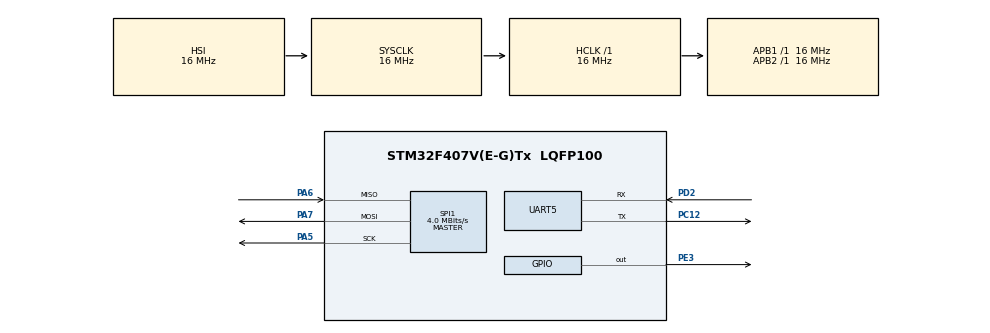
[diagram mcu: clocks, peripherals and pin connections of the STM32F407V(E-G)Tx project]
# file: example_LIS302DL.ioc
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Mcu.Family=STM32F4
Mcu.Name=STM32F407V(E-G)Tx
Mcu.Package=LQFP100
NVIC.PriorityGroup=NVIC_PRIORITYGROUP_4
PA5.Mode=Full_Duplex_Master
PA5.Signal=SPI1_SCK
PA6.Mode=Full_Duplex_Master
PA6.Signal=SPI1_MISO
PA7.Mode=Full_Duplex_Master
PA7.Signal=SPI1_MOSI
PC12.Mode=Asynchronous
PC12.Signal=UART5_TX
PD2.Mode=Asynchronous
PD2.Signal=UART5_RX
PE3.PinState=GPIO_PIN_SET
PE3.Signal=GPIO_Output
ProjectManager.HeapSize=0x200
ProjectManager.StackSize=0x400
ProjectManager.TargetToolchain=MDK-ARM V5.32
RCC.AHBFreq_Value=16000000
RCC.APB1Freq_Value=16000000
RCC.APB2Freq_Value=16000000
RCC.CortexFreq_Value=16000000
RCC.HSE_VALUE=25000000
RCC.HSI_VALUE=16000000
RCC.LSE_VALUE=32768
RCC.SYSCLKFreq_VALUE=16000000
RCC.VCOOutputFreq_Value=192000000
SPI1.BaudRatePrescaler=SPI_BAUDRATEPRESCALER_4
SPI1.CLKPhase=SPI_PHASE_2EDGE
SPI1.CLKPolarity=SPI_POLARITY_HIGH
SPI1.CalculateBaudRate=4.0 MBits/s
SPI1.Direction=SPI_DIRECTION_2LINES
SPI1.Mode=SPI_MODE_MASTER
SPI1.VirtualType=VM_MASTER
UART5.VirtualMode=Asynchronous
board=custom

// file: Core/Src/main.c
/* USER CODE BEGIN Header */
/**
  ******************************************************************************
  * @file           : main.c
  * @brief          : Main program body
  ******************************************************************************
  * @attention
  *
  * Copyright (c) 2026 STMicroelectronics.
  * All rights reserved.
  *
  * This software is licensed under terms that can be found in the LICENSE file
  * in the root directory of this software component.
  * If no LICENSE file comes with this software, it is provided AS-IS.
  *
  ******************************************************************************
  */
/* USER CODE END Header */
#include "main.h"
#include "spi.h"
#include "usart.h"
#include "gpio.h"

void SystemClock_Config(void);
/* USER CODE BEGIN PFP */
uint8_t MEMS_READ_REG(uint8_t reg_addr)
{
  uint8_t read_buf = reg_addr | 0x80;
  uint8_t recv_buf = 0;

  HAL_GPIO_WritePin(GPIOE, GPIO_PIN_3, GPIO_PIN_RESET);
  HAL_SPI_Transmit(&hspi1, &read_buf, 1, HAL_MAX_DELAY);
  HAL_SPI_Receive(&hspi1, &recv_buf, 1, HAL_MAX_DELAY);
  HAL_GPIO_WritePin(GPIOE, GPIO_PIN_3, GPIO_PIN_SET);

  return recv_buf;
}
/* USER CODE END PFP */

int main(void)
{

  /* MCU Configuration--------------------------------------------------------*/

  /* Reset of all peripherals, Initializes the Flash interface and the Systick. */
  HAL_Init();

  /* Configure the system clock */
  SystemClock_Config();

  /* Initialize all configured peripherals */
  MX_GPIO_Init();
  MX_SPI1_Init();
  MX_UART5_Init();
  /* USER CODE BEGIN 2 */
  uint8_t REG_WHO_AM_I = 0x0F;

  uint8_t READ_WHO_AM_I = REG_WHO_AM_I | 0x80;

  uint8_t recv_buf = 0;

  /* USER CODE END 2 */

  /* Infinite loop */
  while (1)
  {

    /* USER CODE BEGIN 3 */
    // HAL_GPIO_WritePin(GPIOE, GPIO_PIN_3, GPIO_PIN_RESET);
    // HAL_SPI_Transmit(&hspi1, &READ_WHO_AM_I, 1, HAL_MAX_DELAY);
    // HAL_SPI_Receive(&hspi1, &recv_buf, 1, HAL_MAX_DELAY);
    // HAL_GPIO_WritePin(GPIOE, GPIO_PIN_3, GPIO_PIN_SET);

    recv_buf = MEMS_READ_REG(REG_WHO_AM_I);

    HAL_UART_Transmit(&huart5, &recv_buf, 1, HAL_MAX_DELAY);
    HAL_Delay(500);

  }
  /* USER CODE END 3 */
}

void SystemClock_Config(void)
{
  RCC_OscInitTypeDef RCC_OscInitStruct = {0};
  RCC_ClkInitTypeDef RCC_ClkInitStruct = {0};

  /** Configure the main internal regulator output voltage
  */
  __HAL_RCC_PWR_CLK_ENABLE();
  __HAL_PWR_VOLTAGESCALING_CONFIG(PWR_REGULATOR_VOLTAGE_SCALE1);

  /** Initializes the RCC Oscillators according to the specified parameters
  * in the RCC_OscInitTypeDef structure.
  */
  RCC_OscInitStruct.OscillatorType = RCC_OSCILLATORTYPE_HSI;
  RCC_OscInitStruct.HSIState = RCC_HSI_ON;
  RCC_OscInitStruct.HSICalibrationValue = RCC_HSICALIBRATION_DEFAULT;
  RCC_OscInitStruct.PLL.PLLState = RCC_PLL_NONE;
  if (HAL_RCC_OscConfig(&RCC_OscInitStruct) != HAL_OK)
  {
    Error_Handler();
  }

  /** Initializes the CPU, AHB and APB buses clocks
  */
  RCC_ClkInitStruct.ClockType = RCC_CLOCKTYPE_HCLK|RCC_CLOCKTYPE_SYSCLK
                              |RCC_CLOCKTYPE_PCLK1|RCC_CLOCKTYPE_PCLK2;
  RCC_ClkInitStruct.SYSCLKSource = RCC_SYSCLKSOURCE_HSI;
  RCC_ClkInitStruct.AHBCLKDivider = RCC_SYSCLK_DIV1;
  RCC_ClkInitStruct.APB1CLKDivider = RCC_HCLK_DIV1;
  RCC_ClkInitStruct.APB2CLKDivider = RCC_HCLK_DIV1;

  if (HAL_RCC_ClockConfig(&RCC_ClkInitStruct, FLASH_LATENCY_0) != HAL_OK)
  {
    Error_Handler();
  }
}

void Error_Handler(void)
{
  __disable_irq();
  while (1)
  {
  }
}
